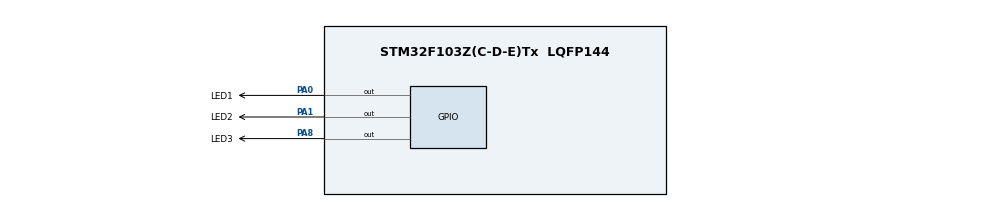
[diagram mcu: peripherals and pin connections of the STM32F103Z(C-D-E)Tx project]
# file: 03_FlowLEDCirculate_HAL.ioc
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Mcu.Family=STM32F1
Mcu.Name=STM32F103Z(C-D-E)Tx
Mcu.Package=LQFP144
NVIC.PriorityGroup=NVIC_PRIORITYGROUP_4
OSC_IN.Mode=HSE-External-Oscillator
OSC_IN.Signal=RCC_OSC_IN
OSC_OUT.Mode=HSE-External-Oscillator
OSC_OUT.Signal=RCC_OSC_OUT
PA0-WKUP.GPIO_Label=LED1
PA0-WKUP.GPIO_Speed=GPIO_SPEED_FREQ_HIGH
PA0-WKUP.PinState=GPIO_PIN_SET
PA0-WKUP.Signal=GPIO_Output
PA1.GPIO_Label=LED2
PA1.GPIO_Speed=GPIO_SPEED_FREQ_HIGH
PA1.PinState=GPIO_PIN_SET
PA1.Signal=GPIO_Output
PA13.Mode=Serial_Wire
PA13.Signal=SYS_JTMS-SWDIO
PA14.Mode=Serial_Wire
PA14.Signal=SYS_JTCK-SWCLK
PA8.GPIO_Label=LED3
PA8.GPIO_Speed=GPIO_SPEED_FREQ_HIGH
PA8.PinState=GPIO_PIN_SET
PA8.Signal=GPIO_Output
PC14-OSC32_IN.Mode=LSE-External-Oscillator
PC14-OSC32_IN.Signal=RCC_OSC32_IN
PC15-OSC32_OUT.Mode=LSE-External-Oscillator
PC15-OSC32_OUT.Signal=RCC_OSC32_OUT
ProjectManager.HeapSize=0x200
ProjectManager.StackSize=0x400
ProjectManager.TargetToolchain=MDK-ARM V5.32
RCC.APB1Freq_Value=8000000
RCC.APB2Freq_Value=8000000
board=custom

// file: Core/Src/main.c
/* USER CODE BEGIN Header */
/**
  ******************************************************************************
  * @file           : main.c
  * @brief          : Main program body
  ******************************************************************************
  * @attention
  *
  * Copyright (c) 2025 STMicroelectronics.
  * All rights reserved.
  *
  * This software is licensed under terms that can be found in the LICENSE file
  * in the root directory of this software component.
  * If no LICENSE file comes with this software, it is provided AS-IS.
  *
  ******************************************************************************
  */
/* USER CODE END Header */
#include "main.h"
#include "gpio.h"

/* USER CODE BEGIN Includes */
#include "Int_LED.h"
/* USER CODE END Includes */

void SystemClock_Config(void);

/* USER CODE BEGIN 0 */
uint16_t leds[3] = {LED1_Pin,LED2_Pin,LED3_Pin};
/* USER CODE END 0 */

int main(void)
{

  /* MCU Configuration--------------------------------------------------------*/

  /* Reset of all peripherals, Initializes the Flash interface and the Systick. */
  HAL_Init();

  /* Configure the system clock */
  SystemClock_Config();

  /* Initialize all configured peripherals */
  MX_GPIO_Init();

  /* Infinite loop */
  while (1)
  {

    /* USER CODE BEGIN 3 */
    // ѭ��LED��ˮ��
    for(uint8_t i = 0;i < 3;i++)
    {
      Int_LED_On(leds[i]);
      HAL_Delay(500);
      Int_LED_Off(leds[i]);
    }

	Int_LED_Toggle(LED2_Pin);
    HAL_Delay(500);
	Int_LED_Toggle(LED2_Pin);
  }
  /* USER CODE END 3 */
}

void SystemClock_Config(void)
{
  RCC_OscInitTypeDef RCC_OscInitStruct = {0};
  RCC_ClkInitTypeDef RCC_ClkInitStruct = {0};

  /** Initializes the RCC Oscillators according to the specified parameters
  * in the RCC_OscInitTypeDef structure.
  */
  RCC_OscInitStruct.OscillatorType = RCC_OSCILLATORTYPE_HSI;
  RCC_OscInitStruct.HSIState = RCC_HSI_ON;
  RCC_OscInitStruct.HSICalibrationValue = RCC_HSICALIBRATION_DEFAULT;
  RCC_OscInitStruct.PLL.PLLState = RCC_PLL_NONE;
  if (HAL_RCC_OscConfig(&RCC_OscInitStruct) != HAL_OK)
  {
    Error_Handler();
  }

  /** Initializes the CPU, AHB and APB buses clocks
  */
  RCC_ClkInitStruct.ClockType = RCC_CLOCKTYPE_HCLK|RCC_CLOCKTYPE_SYSCLK
                              |RCC_CLOCKTYPE_PCLK1|RCC_CLOCKTYPE_PCLK2;
  RCC_ClkInitStruct.SYSCLKSource = RCC_SYSCLKSOURCE_HSI;
  RCC_ClkInitStruct.AHBCLKDivider = RCC_SYSCLK_DIV1;
  RCC_ClkInitStruct.APB1CLKDivider = RCC_HCLK_DIV1;
  RCC_ClkInitStruct.APB2CLKDivider = RCC_HCLK_DIV1;

  if (HAL_RCC_ClockConfig(&RCC_ClkInitStruct, FLASH_LATENCY_0) != HAL_OK)
  {
    Error_Handler();
  }
}

void Error_Handler(void)
{
  __disable_irq();
  while (1)
  {
  }
}
